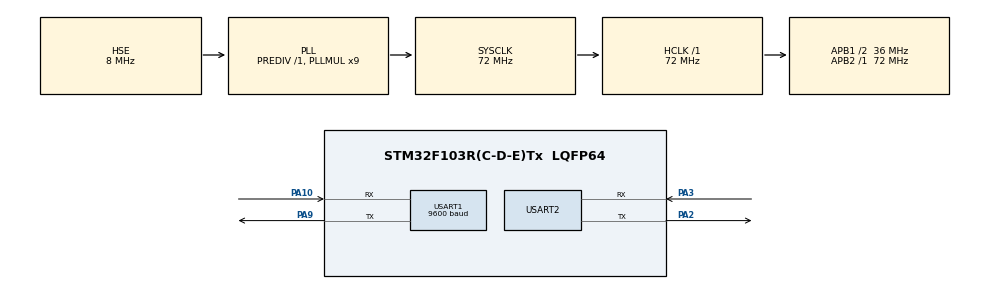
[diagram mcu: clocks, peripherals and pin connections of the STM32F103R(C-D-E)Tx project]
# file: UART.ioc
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Dma.Request0=USART2_RX
Dma.USART2_RX.0.Direction=DMA_PERIPH_TO_MEMORY
Dma.USART2_RX.0.Instance=DMA1_Channel6
Dma.USART2_RX.0.MemDataAlignment=DMA_MDATAALIGN_BYTE
Dma.USART2_RX.0.MemInc=DMA_MINC_ENABLE
Dma.USART2_RX.0.Mode=DMA_NORMAL
Dma.USART2_RX.0.PeriphDataAlignment=DMA_PDATAALIGN_BYTE
Dma.USART2_RX.0.PeriphInc=DMA_PINC_DISABLE
Dma.USART2_RX.0.Priority=DMA_PRIORITY_LOW
Mcu.Family=STM32F1
Mcu.Name=STM32F103R(C-D-E)Tx
Mcu.Package=LQFP64
NVIC.DMA1_Channel6_IRQn=true\:0\:0\:false\:false\:true\:false\:true\:true
NVIC.PriorityGroup=NVIC_PRIORITYGROUP_4
NVIC.USART1_IRQn=true\:0\:0\:false\:false\:true\:true\:true\:true
NVIC.USART2_IRQn=true\:0\:0\:false\:false\:true\:true\:true\:true
PA10.Mode=Asynchronous
PA10.Signal=USART1_RX
PA2.Mode=Asynchronous
PA2.Signal=USART2_TX
PA3.Mode=Asynchronous
PA3.Signal=USART2_RX
PA9.Mode=Asynchronous
PA9.Signal=USART1_TX
PC14-OSC32_IN.Mode=LSE-External-Oscillator
PC14-OSC32_IN.Signal=RCC_OSC32_IN
PC15-OSC32_OUT.Mode=LSE-External-Oscillator
PC15-OSC32_OUT.Signal=RCC_OSC32_OUT
PD0-OSC_IN.Mode=HSE-External-Oscillator
PD0-OSC_IN.Signal=RCC_OSC_IN
PD1-OSC_OUT.Mode=HSE-External-Oscillator
PD1-OSC_OUT.Signal=RCC_OSC_OUT
ProjectManager.HeapSize=0x200
ProjectManager.StackSize=0x400
ProjectManager.TargetToolchain=MDK-ARM V5.32
RCC.AHBFreq_Value=72000000
RCC.APB1CLKDivider=RCC_HCLK_DIV2
RCC.APB1Freq_Value=36000000
RCC.APB1TimFreq_Value=72000000
RCC.APB2Freq_Value=72000000
RCC.APB2TimFreq_Value=72000000
RCC.HCLKFreq_Value=72000000
RCC.PLLMUL=RCC_PLL_MUL9
RCC.PLLSourceVirtual=RCC_PLLSOURCE_HSE
RCC.SYSCLKFreq_VALUE=72000000
RCC.SYSCLKSource=RCC_SYSCLKSOURCE_PLLCLK
RCC.USBFreq_Value=72000000
USART1.BaudRate=9600
USART1.VirtualMode=VM_ASYNC
USART2.VirtualMode=VM_ASYNC
VP_SYS_VS_ND.Mode=No_Debug
board=custom

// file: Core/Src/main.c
/* USER CODE BEGIN Header */
/**
 ******************************************************************************
 * @file           : main.c
 * @brief          : Main program body
 ******************************************************************************
 * @attention
 *
 * Copyright (c) 2023 STMicroelectronics.
 * All rights reserved.
 *
 * This software is licensed under terms that can be found in the LICENSE file
 * in the root directory of this software component.
 * If no LICENSE file comes with this software, it is provided AS-IS.
 *
 ******************************************************************************
 */
/* USER CODE END Header */
#include "main.h"
#include "dma.h"
#include "usart.h"
#include "gpio.h"

/* USER CODE BEGIN Includes */
#include "stdio.h"
#include "string.h"
#include "task.h"
#include "stm32f1xx_it.h"
/* USER CODE END Includes */

/* USER CODE BEGIN PD */
#define LENGTH 10
/* USER CODE END PD */

/* USER CODE BEGIN PV */
uint8_t RxBuffer[LENGTH];
uint8_t RxFlag = 0;
uint8_t RX_COUNT; // 串口接受计数
/* USER CODE END PV */

void SystemClock_Config(void);

int main(void)
{
  /* USER CODE BEGIN 1 */

  // uint8_t temp[10];
  /* USER CODE END 1 */

  /* MCU Configuration--------------------------------------------------------*/

  /* Reset of all peripherals, Initializes the Flash interface and the Systick. */
  HAL_Init();

  /* Configure the system clock */
  SystemClock_Config();

  /* Initialize all configured peripherals */
  MX_GPIO_Init();
  MX_DMA_Init();
  MX_USART2_UART_Init();
  MX_USART1_UART_Init();

  /* Infinite loop */
  /* USER CODE BEGIN WHILE */
  // HAL_UART_Receive_IT(&huart2, (uint8_t *)RxBuffer, LENGTH);//中断接收
  // HAL_UARTEx_ReceiveToIdle_DMA(&huart2, (uint8_t *)RxBuffer, LENGTH);

  HAL_UART_Receive_IT(&huart1, &rx_tmp, 1);
  HAL_UART_Transmit(&huart1, "$PCAS03,1,1,0,0,1,0,1,1,0,0,1,1,1*1E\r\n", 38, 0xff);
  // HAL_Delay(500);
  while (1)
  {

    // HAL_Delay(500);
    //  HAL_UART_Transmit(&huart1, "$PCAS03,1,1,1,1,0,0,1,1,0,0,1,1,1*1F\n", 36, 0xff);
    //  printf("usrt config ok\n");
    //  if (strlen((char *)temp) > 0)
    //  {
    //    printf((char *)temp);
    //    memset(temp, 0, 10);
    //  }
    //  HAL_UART_Receive(&huart2, temp, 10, 0xff);
    Task_Excute(&task_ms);
    // if (RxFlag == 1)
    // {
    //   RxFlag = 0; // 必须清零，防止程序重复进入
    //   RX_COUNT = LENGTH - __HAL_DMA_GET_COUNTER(&hdma_usart2_rx);
    //   HAL_UART_Transmit_IT(&huart2, (uint8_t *)RxBuffer, RX_COUNT);
    //   // HAL_UART_Receive_IT(&huart2, (uint8_t *)RxBuffer, LENGTH);
    //   HAL_UARTEx_ReceiveToIdle_DMA(&huart2, (uint8_t *)RxBuffer, LENGTH);
    // }
    /* USER CODE END WHILE */

  }
}

void SystemClock_Config(void)
{
  RCC_OscInitTypeDef RCC_OscInitStruct = {0};
  RCC_ClkInitTypeDef RCC_ClkInitStruct = {0};

  /** Initializes the RCC Oscillators according to the specified parameters
   * in the RCC_OscInitTypeDef structure.
   */
  RCC_OscInitStruct.OscillatorType = RCC_OSCILLATORTYPE_HSE;
  RCC_OscInitStruct.HSEState = RCC_HSE_ON;
  RCC_OscInitStruct.HSEPredivValue = RCC_HSE_PREDIV_DIV1;
  RCC_OscInitStruct.HSIState = RCC_HSI_ON;
  RCC_OscInitStruct.PLL.PLLState = RCC_PLL_ON;
  RCC_OscInitStruct.PLL.PLLSource = RCC_PLLSOURCE_HSE;
  RCC_OscInitStruct.PLL.PLLMUL = RCC_PLL_MUL9;
  if (HAL_RCC_OscConfig(&RCC_OscInitStruct) != HAL_OK)
  {
    Error_Handler();
  }

  /** Initializes the CPU, AHB and APB buses clocks
   */
  RCC_ClkInitStruct.ClockType = RCC_CLOCKTYPE_HCLK | RCC_CLOCKTYPE_SYSCLK | RCC_CLOCKTYPE_PCLK1 | RCC_CLOCKTYPE_PCLK2;
  RCC_ClkInitStruct.SYSCLKSource = RCC_SYSCLKSOURCE_PLLCLK;
  RCC_ClkInitStruct.AHBCLKDivider = RCC_SYSCLK_DIV1;
  RCC_ClkInitStruct.APB1CLKDivider = RCC_HCLK_DIV2;
  RCC_ClkInitStruct.APB2CLKDivider = RCC_HCLK_DIV1;

  if (HAL_RCC_ClockConfig(&RCC_ClkInitStruct, FLASH_LATENCY_2) != HAL_OK)
  {
    Error_Handler();
  }
}

/* USER CODE BEGIN 4 */
// void HAL_UART_RxCpltCallback(UART_HandleTypeDef *huart)
// {
//   if (huart->Instance == USART2) // 判断是不是串口1引起的中断
//   {
//     RxFlag = 1;
//   }
// }
/* USER CODE END 4 */

void Error_Handler(void)
{
  __disable_irq();
  while (1)
  {
  }
}
